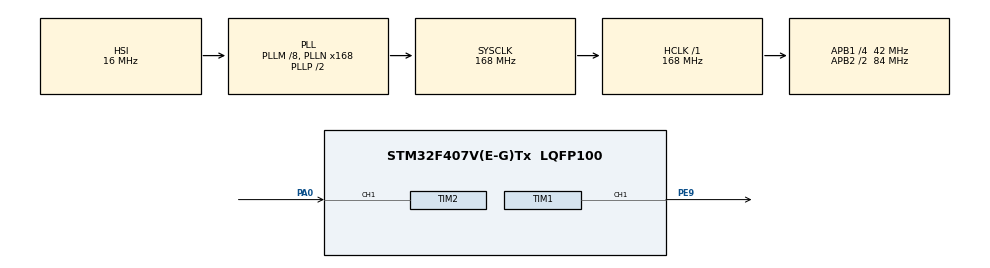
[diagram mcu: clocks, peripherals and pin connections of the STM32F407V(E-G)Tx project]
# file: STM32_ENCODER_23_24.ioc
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Mcu.Family=STM32F4
Mcu.Name=STM32F407V(E-G)Tx
Mcu.Package=LQFP100
NVIC.PriorityGroup=NVIC_PRIORITYGROUP_4
NVIC.TIM2_IRQn=true\:0\:0\:false\:false\:true\:true\:true\:true
PA0-WKUP.Signal=S_TIM2_CH1_ETR
PA13.Mode=Serial_Wire
PA13.Signal=SYS_JTMS-SWDIO
PA14.Mode=Serial_Wire
PA14.Signal=SYS_JTCK-SWCLK
PE9.Signal=S_TIM1_CH1
PH0-OSC_IN.Mode=HSE-External-Oscillator
PH0-OSC_IN.Signal=RCC_OSC_IN
PH1-OSC_OUT.Mode=HSE-External-Oscillator
PH1-OSC_OUT.Signal=RCC_OSC_OUT
ProjectManager.HeapSize=0x200
ProjectManager.StackSize=0x400
ProjectManager.TargetToolchain=STM32CubeIDE
RCC.48MHZClocksFreq_Value=84000000
RCC.AHBFreq_Value=168000000
RCC.APB1CLKDivider=RCC_HCLK_DIV4
RCC.APB1Freq_Value=42000000
RCC.APB1TimFreq_Value=84000000
RCC.APB2CLKDivider=RCC_HCLK_DIV2
RCC.APB2Freq_Value=84000000
RCC.APB2TimFreq_Value=168000000
RCC.CortexFreq_Value=168000000
RCC.HCLKFreq_Value=168000000
RCC.HSE_VALUE=25000000
RCC.HSI_VALUE=16000000
RCC.LSE_VALUE=32768
RCC.PLLM=8
RCC.PLLN=168
RCC.SYSCLKFreq_VALUE=168000000
RCC.SYSCLKSource=RCC_SYSCLKSOURCE_PLLCLK
RCC.VCOOutputFreq_Value=336000000
SH.S_TIM1_CH1.0=TIM1_CH1,PWM Generation1 CH1
SH.S_TIM2_CH1_ETR.0=TIM2_CH1,PWM_Input_1
TIM1.Channel-PWM\ Generation1\ CH1=TIM_CHANNEL_1
TIM1.Period=2800-1
VP_TIM1_VS_ClockSourceINT.Mode=Internal
VP_TIM2_VS_ClockSourceINT.Mode=Internal
board=custom

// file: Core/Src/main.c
/* USER CODE BEGIN Header */
/**
  ******************************************************************************
  * @file           : main.c
  * @brief          : Main program body
  ******************************************************************************
  * @attention
  *
  * Copyright (c) 2023 STMicroelectronics.
  * All rights reserved.
  *
  * This software is licensed under terms that can be found in the LICENSE file
  * in the root directory of this software component.
  * If no LICENSE file comes with this software, it is provided AS-IS.
  *
  ******************************************************************************
  */
/* USER CODE END Header */
#include "main.h"

TIM_HandleTypeDef htim1;
TIM_HandleTypeDef htim2;

/* USER CODE BEGIN PV */
volatile uint32_t Enc_Value = 0;
volatile uint32_t Enc_Freq = 0;
volatile uint32_t Degree_Of_Motor = 0;
#define Main_CH TIM_CHANNEL_1
#define Indirect_CH TIM_CHANNEL_2
#define TIM_CLOCK 84000000
/* USER CODE END PV */

void SystemClock_Config(void);
static void MX_GPIO_Init(void);
static void MX_TIM1_Init(void);
static void MX_TIM2_Init(void);

/* USER CODE BEGIN 0 */

void READ_ENCODER_INIT(TIM_HandleTypeDef *htim, uint32_t Main_Channel,uint32_t Indirect_Channel){
	HAL_TIM_IC_Start_IT(htim, Main_Channel);
	HAL_TIM_IC_Start_IT(htim, Indirect_Channel);
}

void READ_ENCODER(){
	Degree_Of_Motor	= ((HAL_TIM_ReadCapturedValue(&htim2, Indirect_CH)*360) / Enc_Value) % 360 ;	// TIM2--CH2 Indirect Ch
	Enc_Freq = TIM_CLOCK / (Enc_Value*2); 												    		// you can calculate frequency
}

void HAL_TIM_IC_CaptureCallback(TIM_HandleTypeDef *htim){
	if(htim == &htim2){
		if(htim->Channel == HAL_TIM_ACTIVE_CHANNEL_1){
			Enc_Value =	HAL_TIM_ReadCapturedValue(&htim2, Main_CH);  // TIM2--CH1 Main Ch
			if(Enc_Value != 0){
				READ_ENCODER();
			}
		}
	}
}

/* USER CODE END 0 */

int main(void)
{

  /* MCU Configuration--------------------------------------------------------*/

  /* Reset of all peripherals, Initializes the Flash interface and the Systick. */
  HAL_Init();

  /* Configure the system clock */
  SystemClock_Config();

  /* Initialize all configured peripherals */
  MX_GPIO_Init();
  MX_TIM1_Init();
  MX_TIM2_Init();
  /* USER CODE BEGIN 2 */

  READ_ENCODER_INIT(&htim2, Main_CH, Indirect_CH);

  HAL_TIM_PWM_Start(&htim1, TIM_CHANNEL_1);
  TIM1->CCR1=2700;
  /* USER CODE END 2 */

  /* Infinite loop */
  while (1)
  {
	  (TIM1->CCR1)++;
	  HAL_Delay(100);
	  if(TIM1->CCR1 >= TIM1->ARR){
		  TIM1->CCR1=0;
	  }
  }
}

void SystemClock_Config(void)
{
  RCC_OscInitTypeDef RCC_OscInitStruct = {0};
  RCC_ClkInitTypeDef RCC_ClkInitStruct = {0};

  /** Configure the main internal regulator output voltage
  */
  __HAL_RCC_PWR_CLK_ENABLE();
  __HAL_PWR_VOLTAGESCALING_CONFIG(PWR_REGULATOR_VOLTAGE_SCALE1);

  /** Initializes the RCC Oscillators according to the specified parameters
  * in the RCC_OscInitTypeDef structure.
  */
  RCC_OscInitStruct.OscillatorType = RCC_OSCILLATORTYPE_HSI;
  RCC_OscInitStruct.HSIState = RCC_HSI_ON;
  RCC_OscInitStruct.HSICalibrationValue = RCC_HSICALIBRATION_DEFAULT;
  RCC_OscInitStruct.PLL.PLLState = RCC_PLL_ON;
  RCC_OscInitStruct.PLL.PLLSource = RCC_PLLSOURCE_HSI;
  RCC_OscInitStruct.PLL.PLLM = 8;
  RCC_OscInitStruct.PLL.PLLN = 168;
  RCC_OscInitStruct.PLL.PLLP = RCC_PLLP_DIV2;
  RCC_OscInitStruct.PLL.PLLQ = 4;
  if (HAL_RCC_OscConfig(&RCC_OscInitStruct) != HAL_OK)
  {
    Error_Handler();
  }

  /** Initializes the CPU, AHB and APB buses clocks
  */
  RCC_ClkInitStruct.ClockType = RCC_CLOCKTYPE_HCLK|RCC_CLOCKTYPE_SYSCLK
                              |RCC_CLOCKTYPE_PCLK1|RCC_CLOCKTYPE_PCLK2;
  RCC_ClkInitStruct.SYSCLKSource = RCC_SYSCLKSOURCE_PLLCLK;
  RCC_ClkInitStruct.AHBCLKDivider = RCC_SYSCLK_DIV1;
  RCC_ClkInitStruct.APB1CLKDivider = RCC_HCLK_DIV4;
  RCC_ClkInitStruct.APB2CLKDivider = RCC_HCLK_DIV2;

  if (HAL_RCC_ClockConfig(&RCC_ClkInitStruct, FLASH_LATENCY_5) != HAL_OK)
  {
    Error_Handler();
  }
}

static void MX_TIM1_Init(void)
{

  TIM_ClockConfigTypeDef sClockSourceConfig = {0};
  TIM_MasterConfigTypeDef sMasterConfig = {0};
  TIM_OC_InitTypeDef sConfigOC = {0};
  TIM_BreakDeadTimeConfigTypeDef sBreakDeadTimeConfig = {0};

  htim1.Instance = TIM1;
  htim1.Init.Prescaler = 0;
  htim1.Init.CounterMode = TIM_COUNTERMODE_UP;
  htim1.Init.Period = 2800-1;
  htim1.Init.ClockDivision = TIM_CLOCKDIVISION_DIV1;
  htim1.Init.RepetitionCounter = 0;
  htim1.Init.AutoReloadPreload = TIM_AUTORELOAD_PRELOAD_DISABLE;
  if (HAL_TIM_Base_Init(&htim1) != HAL_OK)
  {
    Error_Handler();
  }
  sClockSourceConfig.ClockSource = TIM_CLOCKSOURCE_INTERNAL;
  if (HAL_TIM_ConfigClockSource(&htim1, &sClockSourceConfig) != HAL_OK)
  {
    Error_Handler();
  }
  if (HAL_TIM_PWM_Init(&htim1) != HAL_OK)
  {
    Error_Handler();
  }
  sMasterConfig.MasterOutputTrigger = TIM_TRGO_RESET;
  sMasterConfig.MasterSlaveMode = TIM_MASTERSLAVEMODE_DISABLE;
  if (HAL_TIMEx_MasterConfigSynchronization(&htim1, &sMasterConfig) != HAL_OK)
  {
    Error_Handler();
  }
  sConfigOC.OCMode = TIM_OCMODE_PWM1;
  sConfigOC.Pulse = 0;
  sConfigOC.OCPolarity = TIM_OCPOLARITY_HIGH;
  sConfigOC.OCNPolarity = TIM_OCNPOLARITY_HIGH;
  sConfigOC.OCFastMode = TIM_OCFAST_DISABLE;
  sConfigOC.OCIdleState = TIM_OCIDLESTATE_RESET;
  sConfigOC.OCNIdleState = TIM_OCNIDLESTATE_RESET;
  if (HAL_TIM_PWM_ConfigChannel(&htim1, &sConfigOC, TIM_CHANNEL_1) != HAL_OK)
  {
    Error_Handler();
  }
  sBreakDeadTimeConfig.OffStateRunMode = TIM_OSSR_DISABLE;
  sBreakDeadTimeConfig.OffStateIDLEMode = TIM_OSSI_DISABLE;
  sBreakDeadTimeConfig.LockLevel = TIM_LOCKLEVEL_OFF;
  sBreakDeadTimeConfig.DeadTime = 0;
  sBreakDeadTimeConfig.BreakState = TIM_BREAK_DISABLE;
  sBreakDeadTimeConfig.BreakPolarity = TIM_BREAKPOLARITY_HIGH;
  sBreakDeadTimeConfig.AutomaticOutput = TIM_AUTOMATICOUTPUT_DISABLE;
  if (HAL_TIMEx_ConfigBreakDeadTime(&htim1, &sBreakDeadTimeConfig) != HAL_OK)
  {
    Error_Handler();
  }
  HAL_TIM_MspPostInit(&htim1);

}

static void MX_TIM2_Init(void)
{

  TIM_ClockConfigTypeDef sClockSourceConfig = {0};
  TIM_SlaveConfigTypeDef sSlaveConfig = {0};
  TIM_IC_InitTypeDef sConfigIC = {0};
  TIM_MasterConfigTypeDef sMasterConfig = {0};

  htim2.Instance = TIM2;
  htim2.Init.Prescaler = 0;
  htim2.Init.CounterMode = TIM_COUNTERMODE_UP;
  htim2.Init.Period = 4294967295;
  htim2.Init.ClockDivision = TIM_CLOCKDIVISION_DIV1;
  htim2.Init.AutoReloadPreload = TIM_AUTORELOAD_PRELOAD_DISABLE;
  if (HAL_TIM_Base_Init(&htim2) != HAL_OK)
  {
    Error_Handler();
  }
  sClockSourceConfig.ClockSource = TIM_CLOCKSOURCE_INTERNAL;
  if (HAL_TIM_ConfigClockSource(&htim2, &sClockSourceConfig) != HAL_OK)
  {
    Error_Handler();
  }
  if (HAL_TIM_IC_Init(&htim2) != HAL_OK)
  {
    Error_Handler();
  }
  sSlaveConfig.SlaveMode = TIM_SLAVEMODE_RESET;
  sSlaveConfig.InputTrigger = TIM_TS_TI1FP1;
  sSlaveConfig.TriggerPolarity = TIM_INPUTCHANNELPOLARITY_RISING;
  sSlaveConfig.TriggerPrescaler = TIM_ICPSC_DIV1;
  sSlaveConfig.TriggerFilter = 0;
  if (HAL_TIM_SlaveConfigSynchro(&htim2, &sSlaveConfig) != HAL_OK)
  {
    Error_Handler();
  }
  sConfigIC.ICPolarity = TIM_INPUTCHANNELPOLARITY_RISING;
  sConfigIC.ICSelection = TIM_ICSELECTION_DIRECTTI;
  sConfigIC.ICPrescaler = TIM_ICPSC_DIV1;
  sConfigIC.ICFilter = 0;
  if (HAL_TIM_IC_ConfigChannel(&htim2, &sConfigIC, TIM_CHANNEL_1) != HAL_OK)
  {
    Error_Handler();
  }
  sConfigIC.ICPolarity = TIM_INPUTCHANNELPOLARITY_FALLING;
  sConfigIC.ICSelection = TIM_ICSELECTION_INDIRECTTI;
  if (HAL_TIM_IC_ConfigChannel(&htim2, &sConfigIC, TIM_CHANNEL_2) != HAL_OK)
  {
    Error_Handler();
  }
  sMasterConfig.MasterOutputTrigger = TIM_TRGO_RESET;
  sMasterConfig.MasterSlaveMode = TIM_MASTERSLAVEMODE_DISABLE;
  if (HAL_TIMEx_MasterConfigSynchronization(&htim2, &sMasterConfig) != HAL_OK)
  {
    Error_Handler();
  }

}

static void MX_GPIO_Init(void)
{

  /* GPIO Ports Clock Enable */
  __HAL_RCC_GPIOH_CLK_ENABLE();
  __HAL_RCC_GPIOA_CLK_ENABLE();
  __HAL_RCC_GPIOE_CLK_ENABLE();

}

void Error_Handler(void)
{
  __disable_irq();
  while (1)
  {
  }
}
